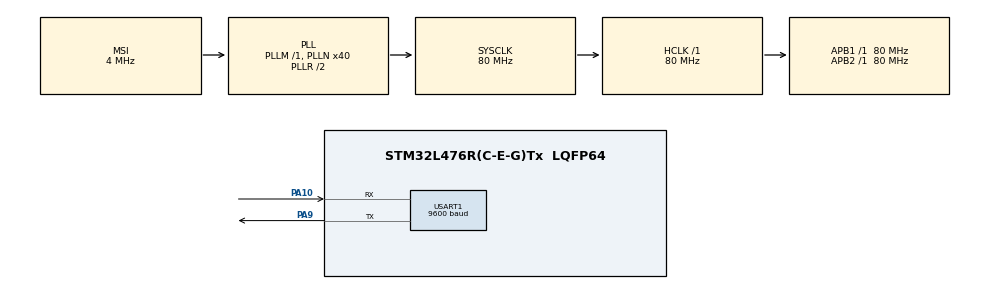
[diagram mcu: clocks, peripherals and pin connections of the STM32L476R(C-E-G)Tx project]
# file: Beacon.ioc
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Dma.Request0=USART1_RX
Dma.Request1=USART1_TX
Dma.USART1_RX.0.Direction=DMA_PERIPH_TO_MEMORY
Dma.USART1_RX.0.Instance=DMA1_Channel5
Dma.USART1_RX.0.MemDataAlignment=DMA_MDATAALIGN_BYTE
Dma.USART1_RX.0.MemInc=DMA_MINC_ENABLE
Dma.USART1_RX.0.Mode=DMA_CIRCULAR
Dma.USART1_RX.0.PeriphDataAlignment=DMA_PDATAALIGN_BYTE
Dma.USART1_RX.0.PeriphInc=DMA_PINC_DISABLE
Dma.USART1_RX.0.Priority=DMA_PRIORITY_LOW
Dma.USART1_TX.1.Direction=DMA_MEMORY_TO_PERIPH
Dma.USART1_TX.1.Instance=DMA1_Channel4
Dma.USART1_TX.1.MemDataAlignment=DMA_MDATAALIGN_BYTE
Dma.USART1_TX.1.MemInc=DMA_MINC_ENABLE
Dma.USART1_TX.1.Mode=DMA_NORMAL
Dma.USART1_TX.1.PeriphDataAlignment=DMA_PDATAALIGN_BYTE
Dma.USART1_TX.1.PeriphInc=DMA_PINC_DISABLE
Dma.USART1_TX.1.Priority=DMA_PRIORITY_LOW
FREERTOS.MEMORY_ALLOCATION=1
FREERTOS.Queues01=DataRx,16,Beacon_t,0,Static,DataRxBuffer,DataRxControlBlock
FREERTOS.Tasks01=defaultTask,0,128,StartDefaultTask,Default,NULL,Static,defaultTaskBuffer,defaultTaskControlBlock;ProcessaDados,0,1024,funcProcessaDados,Default,NULL,Static,ProcessaDadosBuffer,ProcessaDadosControlBlock
Mcu.Family=STM32L4
Mcu.Name=STM32L476R(C-E-G)Tx
Mcu.Package=LQFP64
NVIC.DMA1_Channel4_IRQn=true\:5\:0\:false\:false\:true\:true\:false\:true
NVIC.DMA1_Channel5_IRQn=true\:5\:0\:false\:false\:true\:true\:false\:true
NVIC.PriorityGroup=NVIC_PRIORITYGROUP_4
NVIC.TIM2_IRQn=true\:0\:0\:false\:false\:true\:false\:false\:true
NVIC.TimeBase=TIM2_IRQn
NVIC.TimeBaseIP=TIM2
NVIC.USART1_IRQn=true\:5\:0\:false\:false\:true\:true\:true\:true
PA10.Mode=Asynchronous
PA10.Signal=USART1_RX
PA9.Mode=Asynchronous
PA9.Signal=USART1_TX
ProjectManager.HeapSize=0x200
ProjectManager.StackSize=0x400
ProjectManager.TargetToolchain=STM32CubeIDE
RCC.AHBFreq_Value=80000000
RCC.APB1Freq_Value=80000000
RCC.APB1TimFreq_Value=80000000
RCC.APB2Freq_Value=80000000
RCC.APB2TimFreq_Value=80000000
RCC.CortexFreq_Value=80000000
RCC.HCLKFreq_Value=80000000
RCC.HSE_VALUE=8000000
RCC.HSI_VALUE=16000000
RCC.LSE_VALUE=32768
RCC.MSI_VALUE=4000000
RCC.PLLN=40
RCC.SYSCLKFreq_VALUE=80000000
RCC.SYSCLKSource=RCC_SYSCLKSOURCE_PLLCLK
RCC.VCOOutputFreq_Value=160000000
USART1.BaudRate=9600
USART1.VirtualMode-Asynchronous=VM_ASYNC
VP_FREERTOS_VS_CMSIS_V1.Mode=CMSIS_V1
VP_SYS_VS_tim2.Mode=TIM2
board=custom

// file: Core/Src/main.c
/* USER CODE BEGIN Header */
/**
  ******************************************************************************
  * @file           : main.c
  * @brief          : Main program body
  ******************************************************************************
  * @attention
  *
  * <h2><center>&copy; Copyright (c) 2020 STMicroelectronics.
  * All rights reserved.</center></h2>
  *
  * This software component is licensed by ST under BSD 3-Clause license,
  * the "License"; You may not use this file except in compliance with the
  * License. You may obtain a copy of the License at:
  *                        opensource.org/licenses/BSD-3-Clause
  *
  ******************************************************************************
  */
/* USER CODE END Header */

#include "main.h"
#include "cmsis_os.h"
#include "dma.h"
#include "usart.h"
#include "gpio.h"

void SystemClock_Config(void);
void MX_FREERTOS_Init(void);

int main(void)
{

  /* MCU Configuration--------------------------------------------------------*/

  /* Reset of all peripherals, Initializes the Flash interface and the Systick. */
  HAL_Init();

  /* Configure the system clock */
  SystemClock_Config();

  /* Initialize all configured peripherals */
  MX_GPIO_Init();
  MX_DMA_Init();
  MX_USART1_UART_Init();
  /* USER CODE BEGIN 2 */
  MX_UART1_Start();
  /* USER CODE END 2 */

  /* Call init function for freertos objects (in freertos.c) */
  MX_FREERTOS_Init();
  /* Start scheduler */
  osKernelStart();

  /* We should never get here as control is now taken by the scheduler */
  /* Infinite loop */
  while (1)
  {

  }
}

void SystemClock_Config(void)
{
  RCC_OscInitTypeDef RCC_OscInitStruct = {0};
  RCC_ClkInitTypeDef RCC_ClkInitStruct = {0};
  RCC_PeriphCLKInitTypeDef PeriphClkInit = {0};

  /** Initializes the CPU, AHB and APB busses clocks
  */
  RCC_OscInitStruct.OscillatorType = RCC_OSCILLATORTYPE_MSI;
  RCC_OscInitStruct.MSIState = RCC_MSI_ON;
  RCC_OscInitStruct.MSICalibrationValue = 0;
  RCC_OscInitStruct.MSIClockRange = RCC_MSIRANGE_6;
  RCC_OscInitStruct.PLL.PLLState = RCC_PLL_ON;
  RCC_OscInitStruct.PLL.PLLSource = RCC_PLLSOURCE_MSI;
  RCC_OscInitStruct.PLL.PLLM = 1;
  RCC_OscInitStruct.PLL.PLLN = 40;
  RCC_OscInitStruct.PLL.PLLP = RCC_PLLP_DIV7;
  RCC_OscInitStruct.PLL.PLLQ = RCC_PLLQ_DIV2;
  RCC_OscInitStruct.PLL.PLLR = RCC_PLLR_DIV2;
  if (HAL_RCC_OscConfig(&RCC_OscInitStruct) != HAL_OK)
  {
    Error_Handler();
  }
  /** Initializes the CPU, AHB and APB busses clocks
  */
  RCC_ClkInitStruct.ClockType = RCC_CLOCKTYPE_HCLK|RCC_CLOCKTYPE_SYSCLK
                              |RCC_CLOCKTYPE_PCLK1|RCC_CLOCKTYPE_PCLK2;
  RCC_ClkInitStruct.SYSCLKSource = RCC_SYSCLKSOURCE_PLLCLK;
  RCC_ClkInitStruct.AHBCLKDivider = RCC_SYSCLK_DIV1;
  RCC_ClkInitStruct.APB1CLKDivider = RCC_HCLK_DIV1;
  RCC_ClkInitStruct.APB2CLKDivider = RCC_HCLK_DIV1;

  if (HAL_RCC_ClockConfig(&RCC_ClkInitStruct, FLASH_LATENCY_4) != HAL_OK)
  {
    Error_Handler();
  }
  PeriphClkInit.PeriphClockSelection = RCC_PERIPHCLK_USART1;
  PeriphClkInit.Usart1ClockSelection = RCC_USART1CLKSOURCE_PCLK2;
  if (HAL_RCCEx_PeriphCLKConfig(&PeriphClkInit) != HAL_OK)
  {
    Error_Handler();
  }
  /** Configure the main internal regulator output voltage
  */
  if (HAL_PWREx_ControlVoltageScaling(PWR_REGULATOR_VOLTAGE_SCALE1) != HAL_OK)
  {
    Error_Handler();
  }
}

 /**
  * @brief  Period elapsed callback in non blocking mode
  * @note   This function is called  when TIM2 interrupt took place, inside
  * HAL_TIM_IRQHandler(). It makes a direct call to HAL_IncTick() to increment
  * a global variable "uwTick" used as application time base.
  * @param  htim : TIM handle
  * @retval None
  */
void HAL_TIM_PeriodElapsedCallback(TIM_HandleTypeDef *htim)
{
  if (htim->Instance == TIM2) {
    HAL_IncTick();
  }
}

void Error_Handler(void)
{
}

/************************ (C) COPYRIGHT STMicroelectronics *****END OF FILE****/

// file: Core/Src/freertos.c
/* USER CODE BEGIN Header */
/**
  ******************************************************************************
  * File Name          : freertos.c
  * Description        : Code for freertos applications
  ******************************************************************************
  * @attention
  *
  * <h2><center>&copy; Copyright (c) 2020 STMicroelectronics.
  * All rights reserved.</center></h2>
  *
  * This software component is licensed by ST under Ultimate Liberty license
  * SLA0044, the "License"; You may not use this file except in compliance with
  * the License. You may obtain a copy of the License at:
  *                             www.st.com/SLA0044
  *
  ******************************************************************************
  */
/* USER CODE END Header */

#include "FreeRTOS.h"
#include "task.h"
#include "main.h"
#include "cmsis_os.h"
#include <math.h>

/* USER CODE BEGIN Includes */
#include "usart.h"
/* USER CODE END Includes */

/* USER CODE BEGIN Variables */
#define power_1m -32
#define prop_meio_x10 24.6

/* USER CODE END Variables */
osThreadId defaultTaskHandle;
uint32_t defaultTaskBuffer[ 128 ];
osStaticThreadDef_t defaultTaskControlBlock;
osThreadId ProcessaDadosHandle;
uint32_t ProcessaDadosBuffer[ 1024 ];
osStaticThreadDef_t ProcessaDadosControlBlock;
osMessageQId DataRxHandle;
uint8_t DataRxBuffer[ 16 * sizeof( Beacon_t ) ];
osStaticMessageQDef_t DataRxControlBlock;

/* USER CODE BEGIN FunctionPrototypes */

float_t rssi_to_meter(int8_t rssi);

/* USER CODE END FunctionPrototypes */

void StartDefaultTask(void const * argument);
void funcProcessaDados(void const * argument);

void MX_FREERTOS_Init(void); /* (MISRA C 2004 rule 8.1) */

/* GetIdleTaskMemory prototype (linked to static allocation support) */
void vApplicationGetIdleTaskMemory( StaticTask_t **ppxIdleTaskTCBBuffer, StackType_t **ppxIdleTaskStackBuffer, uint32_t *pulIdleTaskStackSize );

/* USER CODE BEGIN GET_IDLE_TASK_MEMORY */
static StaticTask_t xIdleTaskTCBBuffer;
static StackType_t xIdleStack[configMINIMAL_STACK_SIZE];

void vApplicationGetIdleTaskMemory( StaticTask_t **ppxIdleTaskTCBBuffer, StackType_t **ppxIdleTaskStackBuffer, uint32_t *pulIdleTaskStackSize )
{
  *ppxIdleTaskTCBBuffer = &xIdleTaskTCBBuffer;
  *ppxIdleTaskStackBuffer = &xIdleStack[0];
  *pulIdleTaskStackSize = configMINIMAL_STACK_SIZE;
  /* place for user code */
}
/* USER CODE END GET_IDLE_TASK_MEMORY */

void MX_FREERTOS_Init(void) {

  /* Create the queue(s) */
  /* definition and creation of DataRx */
  osMessageQStaticDef(DataRx, 16, Beacon_t, DataRxBuffer, &DataRxControlBlock);
  DataRxHandle = osMessageCreate(osMessageQ(DataRx), NULL);

  /* Create the thread(s) */
  /* definition and creation of defaultTask */
  osThreadStaticDef(defaultTask, StartDefaultTask, osPriorityNormal, 0, 128, defaultTaskBuffer, &defaultTaskControlBlock);
  defaultTaskHandle = osThreadCreate(osThread(defaultTask), NULL);

  /* definition and creation of ProcessaDados */
  osThreadStaticDef(ProcessaDados, funcProcessaDados, osPriorityNormal, 0, 1024, ProcessaDadosBuffer, &ProcessaDadosControlBlock);
  ProcessaDadosHandle = osThreadCreate(osThread(ProcessaDados), NULL);

}

void StartDefaultTask(void const * argument)
{
  /* USER CODE BEGIN StartDefaultTask */
	uint8_t aTxHdlc[]= {0x7E,0x00,0x04,0x08,0x01,0x41,0x53,0x62};

  /* Infinite loop */
  for(;;)
  {
	  if(UartReady == IDLE)
	  {
		  HAL_UART_Transmit_DMA(&huart1, aTxHdlc, sizeof(aTxHdlc));
		  UartReady = BUSY;
	  }
	  else
	  {
		  osDelay(100);
	  }

	  osDelay(5000);

  }
  /* USER CODE END StartDefaultTask */
}

void funcProcessaDados(void const * argument)
{
  /* USER CODE BEGIN funcProcessaDados */
	float_t dist_B1_B2_Fixa = 1.1;
	float_t distance[64];
	float_t ang_alfa;
	float_t ang_beta;
	float_t d1y1;
	float_t d1y2;
	uint32_t dist_y;
	uint32_t dist_x;
	float_t d1x1;
	float_t d1x2;

	uint16_t panID[64];
	//uint8_t aTxHdlc[127];
	static Beacon_t Device;

	portBASE_TYPE xHigherPriorityTaskWoken = pdTRUE;

	uint8_t cnt = 0;
	uint8_t indice = 0;
  /* Infinite loop */
  for(;;)
  {
	  while(xQueueReceiveFromISR(DataRxHandle, &Device, &xHigherPriorityTaskWoken) == pdTRUE)
	  {
		  if((Device.panId[0]==0x8A&&Device.panId[1]==0x8E)||(Device.panId[0]==0xC9&&Device.panId[1]==0x6F))
		  {
			  cnt++;
			  distance[indice] = rssi_to_meter(Device.rssi);
			  panID[indice++] = ((Device.panId[0]<<8)|Device.panId[1]);
		  }

		  if(indice>1 && indice%2==0)
		  {

			  if((panID[indice-2]==0x8A8E && panID[indice-1]==0xC96F)||(panID[indice-2]==0xC96F && panID[indice-1]==0x8A8E))
			  {
				  if(panID[indice-2]!=panID[indice-1])
				  {
					  ang_alfa = acos((pow(distance[indice-2],2)- pow(dist_B1_B2_Fixa,2) - pow(distance[indice-1],2))/(-2*dist_B1_B2_Fixa*distance[indice-1]));
					  ang_beta = acos((pow(distance[indice-1],2)- pow(dist_B1_B2_Fixa,2) - pow(distance[indice-2],2))/(-2*dist_B1_B2_Fixa*distance[indice-2]));

					  if(ang_alfa>=ang_beta&&distance[indice-2]<=distance[indice-1])
					  {
					  	d1y1 = 1000*(sin(ang_alfa)*distance[indice-2]);
					  	d1y2 = 1000*(sin(ang_beta)*distance[indice-1]);

					  	d1x1 = 1000*(cos(ang_alfa)*distance[indice-2]);
					  	d1x2 = 1000*(cos(ang_beta)*distance[indice-1]);

					  	dist_x = ((d1x1+((1000*dist_B1_B2_Fixa)-d1x2))/2);

					  	dist_y = ((d1y1+d1y2)/2);
					  }

					  if(ang_alfa<=ang_beta&&distance[indice-2]<=distance[indice-1])
					  {
					   	d1y1 = 1000*(sin(ang_beta)*distance[indice-2]);
					  	d1y2 = 1000*(sin(ang_alfa)*distance[indice-1]);

					  	d1x1 = 1000*(cos(ang_beta)*distance[indice-2]);
					  	d1x2 = 1000*(cos(ang_alfa)*distance[indice-1]);

					  	dist_x = ((d1x1+((1000*dist_B1_B2_Fixa)-d1x2))/2);

					  	dist_y = ((d1y1+d1y2)/2);
					  }

					  if(ang_alfa>=ang_beta&&distance[indice-2]>=distance[indice-1])
					  {
					   	d1y1 = 1000*(sin(ang_alfa)*distance[indice-1]);
					   	d1y2 = 1000*(sin(ang_beta)*distance[indice-2]);

					   	d1x1 = 1000*(cos(ang_alfa)*distance[indice-1]);
					   	d1x2 = 1000*(cos(ang_beta)*distance[indice-2]);

					   	dist_x = ((d1x1+((1000*dist_B1_B2_Fixa)-d1x2))/2);

					   	dist_y = ((d1y1+d1y2)/2);
					  }

					  if(ang_alfa<=ang_beta&&distance[indice-2]>=distance[indice-1])
					  {
						d1y1 = 1000*(sin(ang_beta)*distance[indice-1]);
					  	d1y2 = 1000*(sin(ang_alfa)*distance[indice-2]);

					  	d1x2 = 1000*(cos(ang_beta)*distance[indice-1]);
					  	d1x1 = 1000*(cos(ang_alfa)*distance[indice-2]);

					  	dist_x = ((d1x1+((1000*dist_B1_B2_Fixa)-d1x2))/2);

					  	dist_y = ((d1y1+d1y2)/2);
					  }

					  send_x_distance(dist_x);

					  send_y_distance(dist_y);
				  }
			  }
		  }
		  if(indice>63)
		  {
			  indice = 0;
		  }

	  }

//	  if(UartReady == IDLE)
//	 	  {
//	 		  HAL_UART_Transmit_DMA(&huart1, aTxHdlc, tamanho de sua msg);
//	 		  UartReady = BUSY;
//	 	  }
//	 	  else
//	 	  {
//	 		  osDelay(10);
//	 	  }

    osDelay(100);
  }
  /* USER CODE END funcProcessaDados */
}

/* USER CODE BEGIN Application */
float_t rssi_to_meter(int8_t rssi){

    float_t meters = 0;

    meters = pow(10,((power_1m-rssi)/prop_meio_x10));
    return meters;
  }

void send_x_distance(uint32_t value_x){
	uint8_t send_msg[]= {0x7E,0x00,0x1B,0x10,0x01,0x00,0x13,0xA2,0x00,0x40,0xB0,0x98,0x96,0xFF,0xFE,0x00,0x00,0x76,0x61,0x6C,0x6F,0x72,0x78,0x20,0xBF,0xBF,0xBF,0xBF,0xBF,0xBF,0xE8};
	uint8_t divider_x[6];
	long pot_1;
	long pot_2;
	uint8_t count=0;
	uint8_t cont = 0;
	long sum = 0;

	for(count=0;count<6;count++)
	{
		pot_1 = pow(10,6-count);
		pot_2 = pow(10,5-count);

		divider_x[count] = (value_x%(pot_1)/pot_2);

		send_msg[24+count] = 0x30+divider_x[count];
	}

	for(cont=3;cont<30;cont++)
		{
			sum = sum+send_msg[cont];
		}

	send_msg[30] = (0xFF-(sum&0xFF));

	if(UartReady == IDLE)
		  {
			  HAL_UART_Transmit_DMA(&huart1, send_msg, sizeof(send_msg));
			  UartReady = BUSY;
			  osDelay(500);
		  }
		  else
		  {
			  osDelay(100);
		  }

  }

void send_y_distance(uint32_t value_y){
	uint8_t send_msg[]= {0x7E,0x00,0x1B,0x10,0x01,0x00,0x13,0xA2,0x00,0x40,0xB0,0x98,0x96,0xFF,0xFE,0x00,0x00,0x76,0x61,0x6C,0x6F,0x72,0x79,0x20,0xBF,0xBF,0xBF,0xBF,0xBF,0xBF,0xE7};
	uint8_t divider_y[6];
	uint8_t count=0;
	uint8_t cont = 0;
	long pot_1;
	long pot_2;

	long sum = 0;

	for(count=0;count<6;count++)
	{
		pot_1 = pow(10,6-count);
		pot_2 = pow(10,5-count);

		divider_y[count] = (value_y%(pot_1)/pot_2);

		send_msg[24+count] = 0x30+divider_y[count];
	}

	for(cont=3;cont<30;cont++)
	{
		sum = sum+send_msg[cont];
	}
	send_msg[30] = (0xFF-(sum&0xFF));

	if(UartReady == IDLE)
			  {
				  HAL_UART_Transmit_DMA(&huart1, send_msg, sizeof(send_msg));
				  UartReady = BUSY;
				  osDelay(500);
			  }
			  else
			  {
				  osDelay(100);
			  }

  }
/* USER CODE END Application */

/************************ (C) COPYRIGHT STMicroelectronics *****END OF FILE****/
